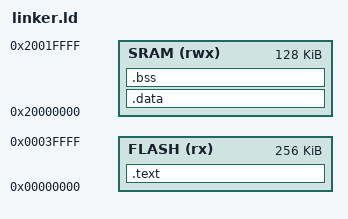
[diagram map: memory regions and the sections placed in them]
MEMORY
{
    FLASH (rx)  : ORIGIN = 0x00000000, LENGTH = 256K
    SRAM  (rwx) : ORIGIN = 0x20000000, LENGTH = 128K
}

ENTRY(Reset_Handler)

SECTIONS
{
    .text : {
        KEEP(*(.isr_vector))
        *(.text*)
        *(.rodata*)
        . = ALIGN(4);
        _etext = .;
    } > FLASH

    .data : AT(_etext) {
        _sdata = .;
        *(.data*)
        . = ALIGN(4);
        _edata = .;
    } > SRAM

    .bss (NOLOAD) : {
        _sbss = .;
        *(.bss*)
        *(COMMON)
        . = ALIGN(4);
        _ebss = .;
    } > SRAM

    _estack = ORIGIN(SRAM) + LENGTH(SRAM);
}
